# COMPUTE_CLUSTER_ARM_COREPACK_0_COMPUTE_CLUSTER_ARM_COREPACK_0_APBADDR_ETM_CPU0_000730040000h register map
Vendor: Texas Instruments
Registers are 32-bit, read-write, reset 0x0 unless marked. A register's access mark holds for its fields unless they carry their own. Offsets are as the file gives them; [hi:lo] are bit positions; {n}, {i} and the like mark numbered series; <NAME> marks a mode.

## COMPUTE_CLUSTER_ARM_COREPACK_0_APBADDR_ETM_CPU0 (part 2 of 2)
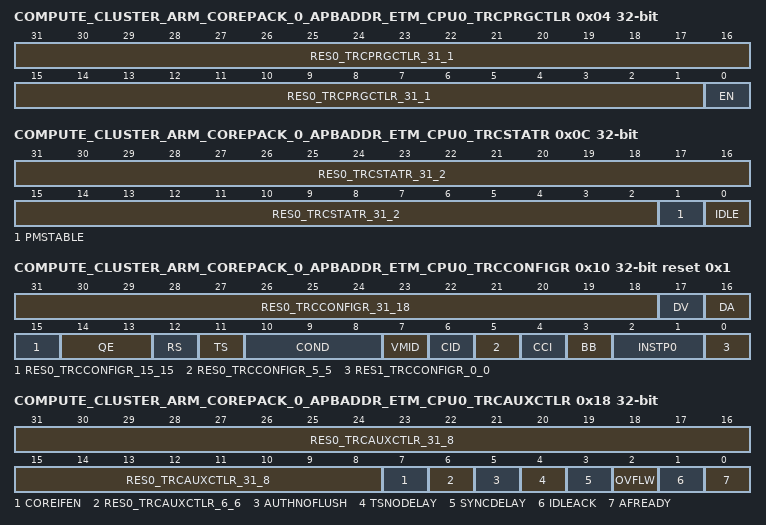
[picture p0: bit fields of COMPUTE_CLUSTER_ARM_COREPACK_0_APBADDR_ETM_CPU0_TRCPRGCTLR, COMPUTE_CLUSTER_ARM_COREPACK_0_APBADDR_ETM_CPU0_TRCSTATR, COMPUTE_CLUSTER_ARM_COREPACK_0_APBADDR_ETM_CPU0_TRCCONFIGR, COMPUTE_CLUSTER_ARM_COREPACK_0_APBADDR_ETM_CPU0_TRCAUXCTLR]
0x04 COMPUTE_CLUSTER_ARM_COREPACK_0_APBADDR_ETM_CPU0_TRCPRGCTLR — Programming Control Register
  [31:1] RES0_TRCPRGCTLR_31_1 — Reserved, RES0.
  [0] EN — Trace unit enable bit. Possible values are: 0 The trace unit is disabled. All trace resources are inactive and no trace is generated. 1 The trace unit is enabled.
0x0C COMPUTE_CLUSTER_ARM_COREPACK_0_APBADDR_ETM_CPU0_TRCSTATR — Status Register
  [31:2] RES0_TRCSTATR_31_2 — Reserved, RES0.
  [1] PMSTABLE — Programmer's model stable bit: 0 The programmer's model is not stable. 1 The programmer's model is stable. When polled, the trace unit trace registers return stable data. The programmer's model is stable when all of the following are true:TRCPRGCTLR.EN==0 or the OS Lock is locked.Reads from trace unit registers return stable data.
  [0] IDLE — Idle status bit: 0 The trace unit is not idle. 1 The trace unit is idle. The trace unit is idle when all of the following are true:TRCPRGCTLR.EN==0 or the OS Lock is locked.The trace unit is drained of any trace.With the exception of the programming interfaces, all external interfaces on the trace unit are quiescent.
0x10 COMPUTE_CLUSTER_ARM_COREPACK_0_APBADDR_ETM_CPU0_TRCCONFIGR reset 0x1 — Trace Configuration Register
  [31:18] RES0_TRCCONFIGR_31_18 — Reserved, RES0.
  [17] DV — Data value tracing bit: 0 Data value tracing is disabled. 1 Data value tracing is enabled when INSTP0 is not 0b00. TRCIDR0.TRCDATA indicates whether this bit is supported. If it is not supported then this bit is RES0.
  [16] DA — Data address tracing bit: 0 Data address tracing is disabled. 1 Data address tracing is enabled when INSTP0 is not 0b00. TRCIDR0.TRCDATA indicates whether this bit is supported. If it is not supported then this bit is RES0.
  [15] RES0_TRCCONFIGR_15_15 — Reserved, RES0.
  [14:13] QE — Q element enable field: 00 Q elements are disabled. 01 Q elements with instruction counts are enabled. Q elements without instruction counts are disabled. 11 Q elements with and without instruction counts are enabled. The value 0b10 is reserved.TRCIDR0.QSUPP indicates which values of this field are implemented.TRCCONFIGR.QE must be set to 0b00 if any of the following are true:TRCCONFIGR.INSTP0 is not 0b00.TRCCONFIGR.COND is not 0b000.TRCCONFIGR.BB is not 0.
  [12] RS — Return stack enable bit. 0 Return stack is disabled. 1 Return stack is enabled. TRCIDR0.RETSTACK indicates whether this bit is supported. If it is not supported then this bit is RES0.
  [11] TS — Global timestamp tracing bit: 0 Global timestamp tracing is disabled. 1 Global timestamp tracing is enabled. TRCTSCTLR controls the insertion of timestamps in the trace. TRCIDR0.TSSIZE indicates whether this bit is supported. If it is not supported then this bit is RES0.
  [10:8] COND — Conditional instruction tracing bit. The permitted values are: 000 Conditional instruction tracing is disabled. 001 Conditional load instructions are traced. 010 Conditional store instructions are traced. 011 Conditional load and store instructions are traced. 111 All conditional instructions are traced. All other values are reserved.TRCIDR0.TRCCOND indicates whether this field is supported. If it is not supported then this field is RES0.
  [7] VMID — VMID tracing bit: 0 VMID tracing is disabled. 1 VMID tracing is enabled. TRCIDR2.VMIDSIZE indicates whether this bit is supported. If it is not supported then this bit is RES0.
  [6] CID — Context ID tracing bit: 0 Context ID tracing is disabled. 1 Context ID tracing is enabled. TRCIDR2.CIDSIZE indicates whether this bit is supported. If it is not supported then this bit is RES0.
  [5] RES0_TRCCONFIGR_5_5 — Reserved, RES0.
  [4] CCI — Cycle counting instruction trace bit: 0 Cycle counting in the instruction trace is disabled. 1 Cycle counting in the instruction trace is enabled. TRCCCCTLR controls the threshold value for cycle counting. TRCIDR0.TRCCCI indicates whether this bit is supported. If it is not supported then this bit is RES0.
  [3] BB — Branch broadcast mode bit: 0 Branch broadcast mode is disabled. 1 Branch broadcast mode is enabled. TRCBBCTLR controls which regions of memory are enabled to use branch broadcasting. TRCIDR0.TRCBB indicates whether this bit is supported. If it is not supported then this bit is RES0.
  [2:1] INSTP0 — Instruction P0 bit. This field controls whether load and store instructions are traced as P0 instructions: 00 Do not trace load and store instructions as P0 instructions. 01 Trace load instructions as P0 instructions. 10 Trace store instructions as P0 instructions. 11 Trace load and store instructions as P0 instructions. TRCIDR0.INSTP0 indicates whether this field is supported. If it is not supported then this field is RES0.
  [0] RES1_TRCCONFIGR_0_0 — Reserved, RES1.
0x18 COMPUTE_CLUSTER_ARM_COREPACK_0_APBADDR_ETM_CPU0_TRCAUXCTLR — Auxiliary Control Register
  [31:8] RES0_TRCAUXCTLR_31_8 — Reserved RES0
  [7] COREIFEN — Keep core interface enabled regardless of trace enable register state
  [6] RES0_TRCAUXCTLR_6_6 — Reserved RES0
  [5] AUTHNOFLUSH — Do not flush trace on de-assertion of authentication inputs. When this bit is set to 1 the trace unit behavior deviates from architecturally-specified behavior.
  [4] TSNODELAY — Do not delay timestamp insertion based on FIFO depth.
  [3] SYNCDELAY — Delay periodic synchronization if FIFO is more than half-full.
  [2] OVFLW — Force an overflow if synchronization is not completed when second synchronization becomes due. When this bit is set to 1 the trace unit behavior deviates from architecturally-specified behavior.
  [1] IDLEACK — Force idle-drain acknowledge high CPU does not wait for trace to drain before entering WFX state. When this bit is set to 1 trace unit behavior deviates from architecturally-specified behavior.
  [0] AFREADY — Always respond to AFREADY immediately. Does not have any interaction with FIFO draining even in WFI state.
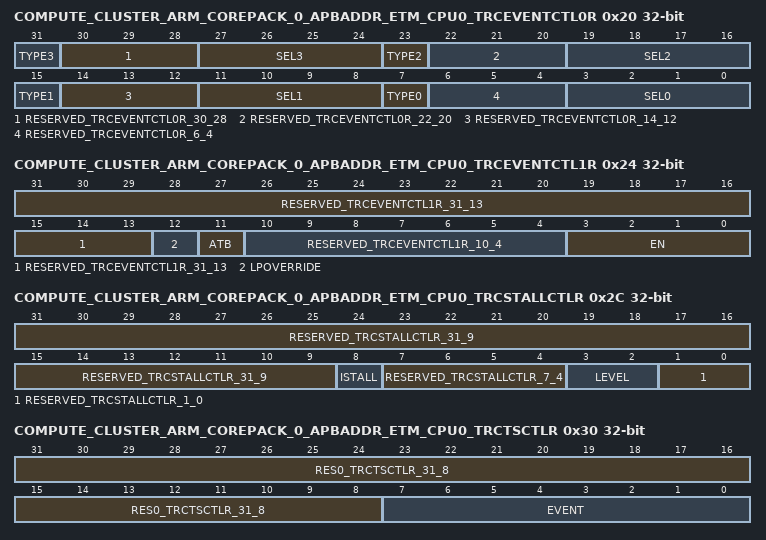
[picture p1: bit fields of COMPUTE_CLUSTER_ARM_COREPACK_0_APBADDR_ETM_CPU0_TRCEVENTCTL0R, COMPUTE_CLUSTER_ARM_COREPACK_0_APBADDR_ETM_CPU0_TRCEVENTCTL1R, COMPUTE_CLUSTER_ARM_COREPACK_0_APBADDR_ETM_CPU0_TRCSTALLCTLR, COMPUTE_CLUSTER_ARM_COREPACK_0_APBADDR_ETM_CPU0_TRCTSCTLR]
0x20 COMPUTE_CLUSTER_ARM_COREPACK_0_APBADDR_ETM_CPU0_TRCEVENTCTL0R — Event Control 0 Register
  [8n+7] TYPE{n} (n=0..3) — Selects the resource type for trace event {n}
  [30:28] RESERVED_TRCEVENTCTL0R_30_28 — Reserved RES0
  [8n+3:8n] SEL{n} (n=0..3) — Selects the resource number based on the value of TYPE{n}
  [22:20] RESERVED_TRCEVENTCTL0R_22_20 — Reserved RES0
  [14:12] RESERVED_TRCEVENTCTL0R_14_12 — Reserved RES0
  [6:4] RESERVED_TRCEVENTCTL0R_6_4 — Reserved RES0
0x24 COMPUTE_CLUSTER_ARM_COREPACK_0_APBADDR_ETM_CPU0_TRCEVENTCTL1R — Event Control 1 Register
  [31:13] RESERVED_TRCEVENTCTL1R_31_13 — Reserved RES0
  [12] LPOVERRIDE — Low power state behavior override
  [11] ATB — ATB trigger enable
  [10:4] RESERVED_TRCEVENTCTL1R_10_4 — Reserved RES0
  [3:0] EN — One bit per event to enable generation of an event element in the instruction trace stream when the selected event occurs
0x2C COMPUTE_CLUSTER_ARM_COREPACK_0_APBADDR_ETM_CPU0_TRCSTALLCTLR — Stall Control Register
  [31:9] RESERVED_TRCSTALLCTLR_31_9 — Reserved RES0
  [8] ISTALL — Controls if the trace unit can stall the processor when the instruction trace buffer space is less than LEVEL
  [7:4] RESERVED_TRCSTALLCTLR_7_4 — Reserved RES0
  [3:2] LEVEL — The field can support 4 monotonic levels from 0b00 to 0b11
  [1:0] RESERVED_TRCSTALLCTLR_1_0 — Reserved RES0
0x30 COMPUTE_CLUSTER_ARM_COREPACK_0_APBADDR_ETM_CPU0_TRCTSCTLR — Global Timestamp Control Register
  [31:8] RES0_TRCTSCTLR_31_8 — Reserved, RES0.
  [7:0] EVENT — An event selector. When the selected event is triggered, the trace unit inserts a global timestamp into the trace streams.
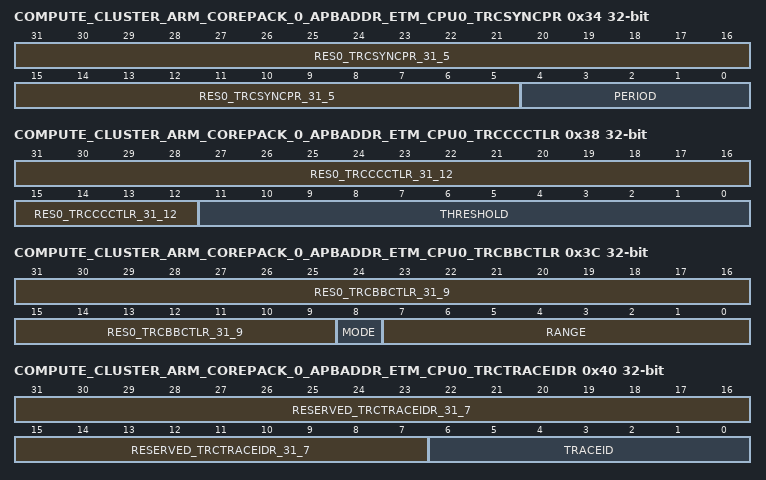
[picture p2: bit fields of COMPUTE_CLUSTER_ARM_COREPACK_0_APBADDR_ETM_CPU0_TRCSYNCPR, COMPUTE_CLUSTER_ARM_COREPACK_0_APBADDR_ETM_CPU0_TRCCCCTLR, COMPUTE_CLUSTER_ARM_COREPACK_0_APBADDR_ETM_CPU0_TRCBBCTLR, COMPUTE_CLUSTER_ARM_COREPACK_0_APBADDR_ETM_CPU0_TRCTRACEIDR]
0x34 COMPUTE_CLUSTER_ARM_COREPACK_0_APBADDR_ETM_CPU0_TRCSYNCPR — Synchronization Period Register
  [31:5] RES0_TRCSYNCPR_31_5 — Reserved, RES0.
  [4:0] PERIOD — Controls how many bytes of trace, the sum of instruction and data, that a trace unit can generate before a periodic trace synchronization request occurs. The number of bytes is always a power of two and the permitted values are: 00000 Periodic trace synchronization requests are disabled. This setting does not disable other types of trace synchronization request. 01000 Periodic trace synchronization request occurs after 2^8, or 256, bytes of trace. 01001 Periodic trace synchronization request occurs after 2^9, or 512, bytes of trace. 01010 Periodic trace synchronization request occurs after 2^10, or 1024, bytes of trace. and so on up to 0b10100, for which the request occurs after 2^20, or 1048576, bytes of trace.Values between 0b00001 and 0b001111 are reserved, as are values from 0b10101 onwards.
0x38 COMPUTE_CLUSTER_ARM_COREPACK_0_APBADDR_ETM_CPU0_TRCCCCTLR — Cycle Count Control Register
  [31:12] RES0_TRCCCCTLR_31_12 — Reserved, RES0.
  [11:0] THRESHOLD — Sets the threshold value for instruction trace cycle counting.The minimum threshold value that can be programmed into THRESHOLD is given in TRCIDR3.CCITMIN.Writing a value of zero might cause UNPREDICTABLE behaviour.
0x3C COMPUTE_CLUSTER_ARM_COREPACK_0_APBADDR_ETM_CPU0_TRCBBCTLR — Branch Broadcast Control Register
  [31:9] RES0_TRCBBCTLR_31_9 — Reserved, RES0.
  [8] MODE — Mode bit: 0 Exclude mode. Branch broadcasting is not enabled in the address range that RANGE defines. If RANGE==0 then branch broadcasting is enabled for the entire memory map. 1 Include mode. Branch broadcasting is enabled in the address range that RANGE defines. If RANGE==0 then the branch broadcasting behavior is UNPREDICTABLE.
  [7:0] RANGE — Address range field. Selects which address range comparator pairs are in use with branch broadcasting. Each bit represents an address range comparator pair, so bit[n] controls the selection of address range comparator pair n. If bit[n] is: 0 The address range that address range comparator pair n defines is not selected. 1 The address range that address range comparator pair n defines is selected.
0x40 COMPUTE_CLUSTER_ARM_COREPACK_0_APBADDR_ETM_CPU0_TRCTRACEIDR — Trace ID Register
  [31:7] RESERVED_TRCTRACEIDR_31_7 — Reserved RES0
  [6:0] TRACEID — Trace ID value. When only instruction tracing is enabled this provides the trace ID.
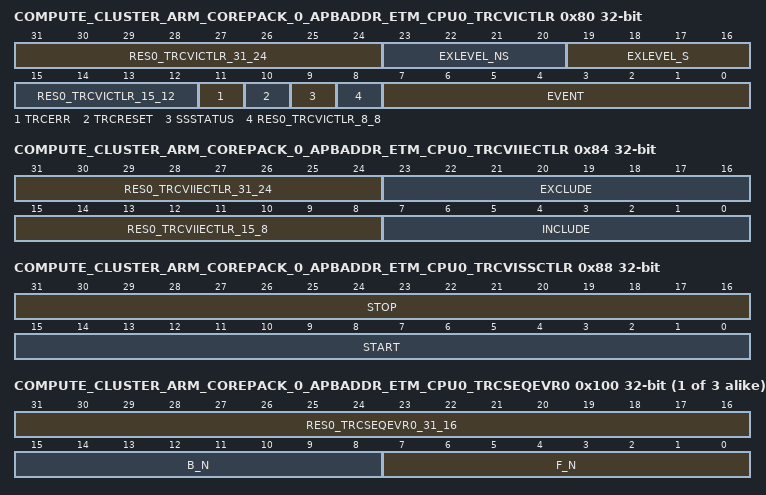
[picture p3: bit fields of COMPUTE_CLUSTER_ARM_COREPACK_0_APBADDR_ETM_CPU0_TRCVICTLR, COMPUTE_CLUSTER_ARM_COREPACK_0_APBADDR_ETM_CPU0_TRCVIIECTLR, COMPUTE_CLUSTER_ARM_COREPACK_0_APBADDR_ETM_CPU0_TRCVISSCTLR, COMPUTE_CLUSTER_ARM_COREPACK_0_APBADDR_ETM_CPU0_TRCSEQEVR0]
0x80 COMPUTE_CLUSTER_ARM_COREPACK_0_APBADDR_ETM_CPU0_TRCVICTLR — ViewInst Main Control Register
  [31:24] RES0_TRCVICTLR_31_24 — Reserved, RES0.
  [23:20] EXLEVEL_NS — In Non-secure state, each bit controls whether instruction tracing is enabled for the corresponding exception level: 0 The trace unit generates instruction trace, in Non-secure state, for exception level n. 1 The trace unit does not generate instruction trace, in Non-secure state, for exception level n. The exception levels are:Bit[20]Exception level 0.Bit[21]Exception level 1.Bit[22]Exception level 2.Bit[23]RAZ/WI. EXLEVEL_NS[3] is never implemented.The content of the field is IMPLEMENTATION DEFINED and is set by the value of TRCIDR3.EXLEVEL_NS. If instruction tracing is not implemented for a given exception level, the corresponding bit in this field is not implemented. Unimplemented bits are RAZ/WI.
  [19:16] EXLEVEL_S — In Secure state, each bit controls whether instruction tracing is enabled for the corresponding exception level: 0 The trace unit generates instruction trace, in Secure state, for exception level n. 1 The trace unit does not generate instruction trace, in Secure state, for exception level n. The exception levels are:Bit[16]Exception level 0.Bit[17]Exception level 1.Bit[18]RAZ/WI. EXLEVEL_S[2] is never implemented.Bit[19]Exception level 3.The content of the field is IMPLEMENTATION DEFINED and is set by the value of TRCIDR3.EXLEVEL_S. If instruction tracing is not implemented for a given exception level, the corresponding bit in this field is not implemented. Unimplemented bits are RAZ/WI.
  [15:12] RES0_TRCVICTLR_15_12 — Reserved, RES0.
  [11] TRCERR — If TRCIDR3.TRCERR==1, this bit controls whether a trace unit must trace a system error exception: 0 The trace unit does not trace a system error exception unless it traces the exception or instruction immediately prior to the system error exception. 1 The trace unit always traces a system error exception. If TRCIDR3.TRCERR==0, this bit is RES0.
  [10] TRCRESET — Controls whether a trace unit must trace a Reset exception: 0 The trace unit does not trace a Reset exception unless it traces the exception or instruction immediately prior to the Reset exception. 1 The trace unit always traces a Reset exception.
  [9] SSSTATUS — IF TRCIDR4.NUMACPAIRS>0 or TRCIDR.NUMPC>0, this bit returns the status of the start-stop logic: 0 The start-stop logic is in the stopped state. 1 The start-stop logic is in the started state. The bit only returns stable data when TRCSTATR.PMSTABLE==1.Before software enables the trace unit, TRCPRGCTLR.EN==1, it must write to this bit to set the initial state of the start-stop logic. If the start-stop logic is not used then set this bit to 1. ARM recommends that the value of this bit is set before each trace run begins.If TRCIDR4.NUMACPAIRS==0 and TRCIDR4.NUMPC==0, this bit is RES0, indicating that the start-stop logic is not implemented.
  [8] RES0_TRCVICTLR_8_8 — Reserved, RES0.
  [7:0] EVENT — An event selector. [TODO: Add the bit assignments for EVENT fields into the descriptions directly?]
0x84 COMPUTE_CLUSTER_ARM_COREPACK_0_APBADDR_ETM_CPU0_TRCVIIECTLR — ViewInst Include-Exclude Control Register
  [31:24] RES0_TRCVIIECTLR_31_24 — Reserved, RES0.
  [23:16] EXCLUDE — 0 1 The implemented width of the field, n, is IMPLEMENTATION DEFINED and is set by the value of TRCIDR4.NUMACPAIRS. Unimplemented bits are RAZ/WI.
  [15:8] RES0_TRCVIIECTLR_15_8 — Reserved, RES0.
  [7:0] INCLUDE — Include range field. Selects which address range comparator pairs are in use with ViewInst include control. Each bit represents an address range comparator pair, so bit[m] controls the selection of address range comparator pair m. If bit[m] is: 0 The address range that address range comparator pair m defines is not selected for ViewInst include control. 1 The address range that address range comparator pair m defines is selected for ViewInst include control. The implemented width of the field, n, is IMPLEMENTATION DEFINED and is set by the value of TRCIDR4.NUMACPAIRS. Unimplemented bits are RAZ/WI.Selecting no include comparators indicates that all instructions are included by default. The exclude control then indicates which ranges are excluded.
0x88 COMPUTE_CLUSTER_ARM_COREPACK_0_APBADDR_ETM_CPU0_TRCVISSCTLR — ViewInst Start-Stop Control Register
  [31:16] STOP — Selects which single address comparators are in use with ViewInst start-stop control, for the purpose of stopping trace. Each bit represents a single address comparator, so bit[m] controls the selection of single address comparator m-16. If bit[m] is: 0 The single address comparator m-16 is not selected as a stop resource. 1 The single address comparator m-16 is selected as a stop resource. The implemented width of the field, n, is IMPLEMENTATION DEFINED and is set by the value of 2 x TRCIDR4.NUMACPAIRS. Unimplemented bits are RAZ/WI.
  [15:0] START — Selects which single address comparators are in use with ViewInst start-stop control, for the purpose of starting trace. Each bit represents a single address comparator, so bit[n] controls the selection of single address comparator n. If bit[n] is: 0 The single address comparator n is not selected as a start resource. 1 The single address comparator n is selected as a start resource. The implemented width of the field, n, is IMPLEMENTATION DEFINED and is set by the value of 2 x TRCIDR4.NUMACPAIRS. Unimplemented bits are RAZ/WI.
{0x100+4i} COMPUTE_CLUSTER_ARM_COREPACK_0_APBADDR_ETM_CPU0_TRCSEQEVR{i} (i=0..2) — Sequencer State Transition Control Registers {i}
  [31:16] RES0_TRCSEQEVR{i}_31_16 — Reserved, RES0.
  [15:8] B_N — Backward field. Contains an event number. When the event occurs then the sequencer state moves from state n+1 to state n.For example, for TRCSEQEVR2, if B2==0x14 then when event 0x14 occurs, the sequencer moves from state 3 to state 2.
  [7:0] F_N — Forward field. Contains an event number. When the event occurs then the sequencer state moves from state n to state n+1.For example, for TRCSEQEVR1, if F1==0x12 then when event 0x12 occurs, the sequencer moves from state 1 to state 2.
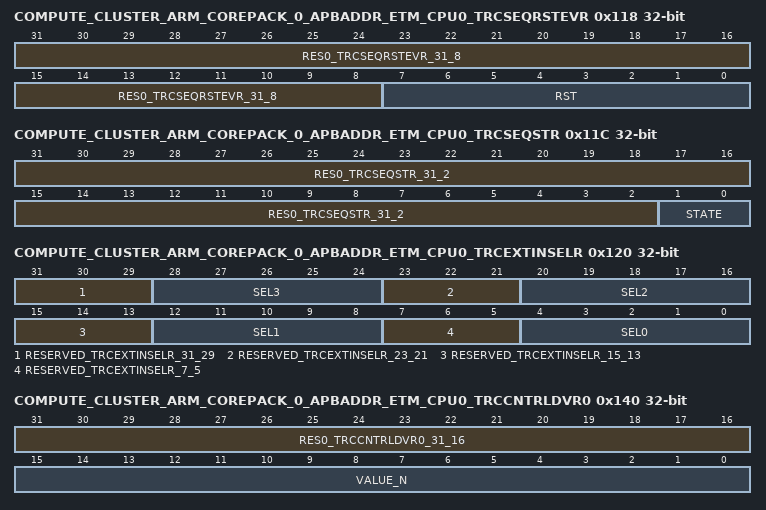
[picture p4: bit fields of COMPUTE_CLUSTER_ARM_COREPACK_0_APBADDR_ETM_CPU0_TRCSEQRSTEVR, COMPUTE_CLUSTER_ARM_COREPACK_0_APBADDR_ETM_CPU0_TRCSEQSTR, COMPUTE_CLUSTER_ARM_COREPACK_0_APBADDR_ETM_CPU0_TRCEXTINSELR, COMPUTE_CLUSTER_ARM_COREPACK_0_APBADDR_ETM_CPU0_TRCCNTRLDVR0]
0x118 COMPUTE_CLUSTER_ARM_COREPACK_0_APBADDR_ETM_CPU0_TRCSEQRSTEVR — Sequencer Reset Control Register
  [31:8] RES0_TRCSEQRSTEVR_31_8 — Reserved, RES0.
  [7:0] RST — Contains an event number. When the event occurs then the sequencer state moves to state 0.
0x11C COMPUTE_CLUSTER_ARM_COREPACK_0_APBADDR_ETM_CPU0_TRCSEQSTR — Sequencer State Register
  [31:2] RES0_TRCSEQSTR_31_2 — Reserved, RES0.
  [1:0] STATE — Sets or returns the state of the sequencer: 00 State 0. 01 State 1. 10 State 2. 11 State 3.
0x120 COMPUTE_CLUSTER_ARM_COREPACK_0_APBADDR_ETM_CPU0_TRCEXTINSELR — External Input Select Register
  [31:29] RESERVED_TRCEXTINSELR_31_29 — Reserved RES0
  [28:24] SEL3 — Selects an event from the external input bus for External Input Resource 3.
  [23:21] RESERVED_TRCEXTINSELR_23_21 — Reserved RES0
  [20:16] SEL2 — Selects an event from the external input bus for External Input Resource 2
  [15:13] RESERVED_TRCEXTINSELR_15_13 — Reserved RES0
  [12:8] SEL1 — Selects an event from the external input bus for External Input Resource 1
  [7:5] RESERVED_TRCEXTINSELR_7_5 — Reserved RES0
  [4:0] SEL0 — Selects an event from the external input bus for External Input Resource 0
0x140 COMPUTE_CLUSTER_ARM_COREPACK_0_APBADDR_ETM_CPU0_TRCCNTRLDVR0 — Counter Reload Value Registers 0
  [31:16] RES0_TRCCNTRLDVR0_31_16 — Reserved, RES0.
  [15:0] VALUE_N — Contains the reload value for counter <n>. When a reload event occurs for counter <n> then the trace unit copies the VALUE<n> field into counter <n>.
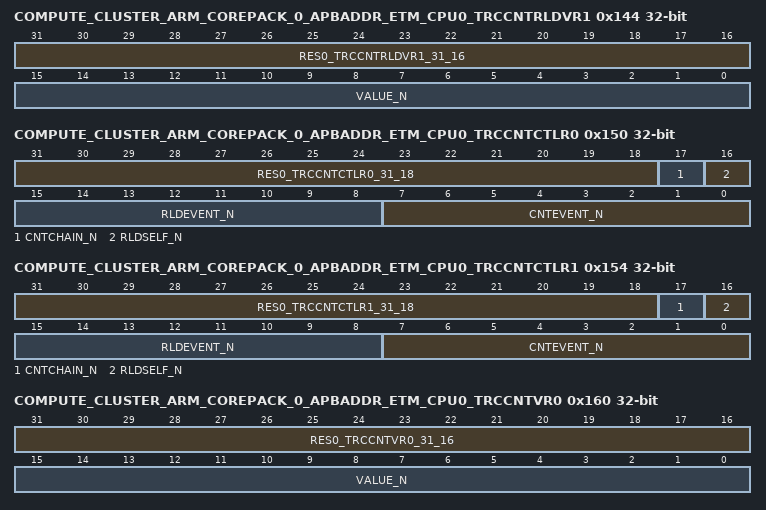
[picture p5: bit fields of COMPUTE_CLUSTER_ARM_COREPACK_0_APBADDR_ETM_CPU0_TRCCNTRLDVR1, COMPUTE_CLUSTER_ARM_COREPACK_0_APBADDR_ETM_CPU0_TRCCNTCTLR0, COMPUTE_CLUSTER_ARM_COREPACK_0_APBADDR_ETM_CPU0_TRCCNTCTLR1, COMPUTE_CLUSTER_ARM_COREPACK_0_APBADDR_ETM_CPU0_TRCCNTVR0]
0x144 COMPUTE_CLUSTER_ARM_COREPACK_0_APBADDR_ETM_CPU0_TRCCNTRLDVR1 — Counter Reload Value Registers 1
  [31:16] RES0_TRCCNTRLDVR1_31_16 — Reserved, RES0.
  [15:0] VALUE_N — Contains the reload value for counter <n>. When a reload event occurs for counter <n> then the trace unit copies the VALUE<n> field into counter <n>.
0x150 COMPUTE_CLUSTER_ARM_COREPACK_0_APBADDR_ETM_CPU0_TRCCNTCTLR0 — Counter Control Register 0
  [31:18] RES0_TRCCNTCTLR0_31_18 — Reserved, RES0.
  [17] CNTCHAIN_N — For TRCCNTCTLR3 and TRCCNTCTLR1, controls whether counter <n> decrements when a reload event occurs for counter <n-1>: 0 1 For TRCCNTCTLR2 and TRCCNTCTLR0, this bit is RES0.
  [16] RLDSELF_N — Controls whether a reload event occurs for counter <n>, when counter <n> reaches zero: 0 The trace unit does not generate a reload event. 1 The trace unit generates a reload event for counter <n>, provided that the event resource that CNTEVENT<n> specifies is active.
  [15:8] RLDEVENT_N — Selects an event, that when it occurs causes a reload event for counter <n>.
  [7:0] CNTEVENT_N — Selects an event, that when it occurs causes counter <n> to decrement.
0x154 COMPUTE_CLUSTER_ARM_COREPACK_0_APBADDR_ETM_CPU0_TRCCNTCTLR1 — Counter Control Register 1
  [31:18] RES0_TRCCNTCTLR1_31_18 — Reserved, RES0.
  [17] CNTCHAIN_N — For TRCCNTCTLR3 and TRCCNTCTLR1, controls whether counter <n> decrements when a reload event occurs for counter <n-1>: 0 1 For TRCCNTCTLR2 and TRCCNTCTLR0, this bit is RES0.
  [16] RLDSELF_N — Controls whether a reload event occurs for counter <n>, when counter <n> reaches zero: 0 The trace unit does not generate a reload event. 1 The trace unit generates a reload event for counter <n>, provided that the event resource that CNTEVENT<n> specifies is active.
  [15:8] RLDEVENT_N — Selects an event, that when it occurs causes a reload event for counter <n>.
  [7:0] CNTEVENT_N — Selects an event, that when it occurs causes counter <n> to decrement.
0x160 COMPUTE_CLUSTER_ARM_COREPACK_0_APBADDR_ETM_CPU0_TRCCNTVR0 — Counter Value Registers 0
  [31:16] RES0_TRCCNTVR0_31_16 — Reserved, RES0.
  [15:0] VALUE_N — Contains the count value of counter <n>.
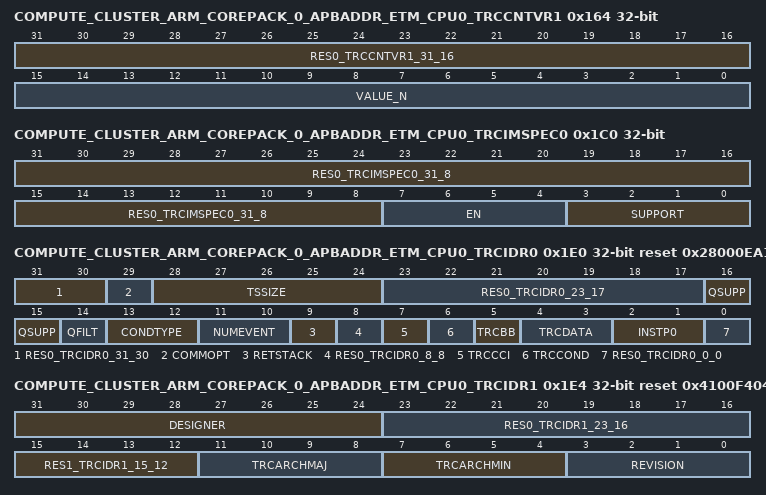
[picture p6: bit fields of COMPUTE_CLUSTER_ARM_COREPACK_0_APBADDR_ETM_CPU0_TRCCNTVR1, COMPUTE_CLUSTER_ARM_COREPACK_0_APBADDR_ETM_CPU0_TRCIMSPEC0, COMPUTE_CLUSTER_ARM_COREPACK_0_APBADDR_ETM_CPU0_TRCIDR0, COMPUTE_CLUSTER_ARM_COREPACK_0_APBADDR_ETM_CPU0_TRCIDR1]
0x164 COMPUTE_CLUSTER_ARM_COREPACK_0_APBADDR_ETM_CPU0_TRCCNTVR1 — Counter Value Registers 1
  [31:16] RES0_TRCCNTVR1_31_16 — Reserved, RES0.
  [15:0] VALUE_N — Contains the count value of counter <n>.
0x180 COMPUTE_CLUSTER_ARM_COREPACK_0_APBADDR_ETM_CPU0_TRCIDR8 — ID Register 8
  [31:0] MAXSPEC — Indicates the maximum speculation depth of the instruction trace stream. This is the maximum number of P0 elements in the trace stream that can be speculative at any time.
0x184 COMPUTE_CLUSTER_ARM_COREPACK_0_APBADDR_ETM_CPU0_TRCIDR9 — ID Register 9
  [31:0] NUMP0KEY — Indicates the number of P0 right-hand keys that the trace unit can use. A value of 0 or 1 indicates one P0 key.
0x188 COMPUTE_CLUSTER_ARM_COREPACK_0_APBADDR_ETM_CPU0_TRCIDR10 — ID Register 10
  [31:0] NUMP1KEY — Indicates the number of P1 right-hand keys that the trace unit can use. The number includes normal and special keys.
0x18C COMPUTE_CLUSTER_ARM_COREPACK_0_APBADDR_ETM_CPU0_TRCIDR11 — ID Register 11
  [31:0] NUMP1SPC — Indicates the number of special P1 right-hand keys that the trace unit can use.
0x190 COMPUTE_CLUSTER_ARM_COREPACK_0_APBADDR_ETM_CPU0_TRCIDR12 — ID Register 12
  [31:0] NUMCONDKEY — Indicates the number of conditional instruction right-hand keys that the trace unit can use. The number includes normal and special keys.
0x194 COMPUTE_CLUSTER_ARM_COREPACK_0_APBADDR_ETM_CPU0_TRCIDR13 — ID Register 13
  [31:0] NUMCONDSPC — Indicates the number of special conditional instruction right-hand keys that the trace unit can use.
0x1C0 COMPUTE_CLUSTER_ARM_COREPACK_0_APBADDR_ETM_CPU0_TRCIMSPEC0 — Implementation Specific Register 0
  [31:8] RES0_TRCIMSPEC0_31_8 — Reserved, RES0.
  [7:4] EN — If SUPPORT is not 0b0000, controls whether the IMPLEMENTATION DEFINED features are enabled. The permitted values are: 0000 The IMPLEMENTATION DEFINED features are not enabled. The trace unit must behave as if the IMPLEMENTATION DEFINED features are not supported. and any other value, which indicates that the trace unit behavior is IMPLEMENTATION DEFINED.If SUPPORT is 0b0000, this field is RES0.
  [3:0] SUPPORT — Indicates whether the implementation supports IMPLEMENTATION DEFINED features. The permitted values are: 0000 No IMPLEMENTATION DEFINED features are supported. The EN field is RES0. and any other value, which indicates that IMPLEMENTATION DEFINED features are supported. Use of these values requires written permission from ARM.
0x1E0 COMPUTE_CLUSTER_ARM_COREPACK_0_APBADDR_ETM_CPU0_TRCIDR0 reset 0x28000EA1 — ID Register 0
  [31:30] RES0_TRCIDR0_31_30 — Reserved, RES0.
  [29] COMMOPT — Conditional instruction tracing support bit. Indicates if the trace unit supports conditional instruction tracing: 0 Conditional instruction tracing is not supported. 1 Conditional instruction tracing is supported, so TRCCONFIGR.COND is supported.
  [28:24] TSSIZE — Global timestamp size field. The permitted values are: 00000 Global timestamping is not implemented. 00110 Implementation supports a maximum global timestamp of 48bits. 01000 Implementation supports a maximum global timestamp of 64bits. All other values are reserved.When global timestamping is implemented then TRCCONFIGR.TS and TRCTSCTLR are supported.
  [23:17] RES0_TRCIDR0_23_17 — Reserved, RES0.
  [16:15] QSUPP — Q element support field. The permitted values are: 00 Q element support is not implemented. TRCCONFIGR.QE is RES0. 01 Q element support is implemented, and only supports Q elements with instruction counts. TRCCONFIGR.QE can only take the values 0b00 or 0b01. 10 Q element support is implemented, and only supports Q elements without instruction counts. TRCCONFIGR.QE can only take the values 0b00 or 0b11. 11 Q element support is implemented, and supports both Q elements with instruction counts and Q elements without instruction counts. TRCCONFIGR.QE is fully implemented.
  [14] QFILT — Q element filtering support field. The permitted values are: 0 Q element filtering is not implemented. 1 Q element filtering is implemented. TRCQCTLR is implemented. When QSUPP==0b00, this field is RES0.
  [13:12] CONDTYPE — Conditional tracing field. The permitted values are: 00 The trace unit indicates only if a conditional instruction is a pass or fail. 01 The trace unit provides the Current Program Status Register [CPSR] status, for a conditional instruction. All other values are reserved.
  [11:10] NUMEVENT — Number of events field. Indicates how many events the trace unit supports: 00 The trace unit supports 1 event. 01 The trace unit supports 2 events. 10 The trace unit supports 3 events. 11 The trace unit supports 4 events. This field controls how many fields are supported in TRCEVENTCTL0R, and indicates the size of TRCEVENTCTL1R.INSTEN.
  [9] RETSTACK — Return stack bit. Indicates if the implementation supports a return stack: 0 Return stack is not implemented. 1 Return stack is implemented, so TRCCONFIGR.RS is supported.
  [8] RES0_TRCIDR0_8_8 — Reserved, RES0.
  [7] TRCCCI — Cycle counting instruction bit. Indicates if the trace unit supports cycle counting for instructions: 0 Cycle counting in the instruction trace is not implemented. 1 Cycle counting in the instruction trace is implemented, so TRCCONFIGR.CCI and TRCCCCTLR are supported.
  [6] TRCCOND — Conditional instruction tracing support bit. Indicates if the trace unit supports conditional instruction tracing: 0 Conditional instruction tracing is not supported. 1 Conditional instruction tracing is supported, so TRCCONFIGR.COND is supported.
  [5] TRCBB — Branch broadcast tracing support bit. Indicates if the trace unit supports branch broadcast tracing: 0 Branch broadcast tracing is not supported. 1 Branch broadcast tracing is supported, so TRCCONFIGR.BB and TRCBBCTLR are supported.
  [4:3] TRCDATA — Conditional tracing field. The permitted values are: 00 Data tracing is not supported. 11 Tracing of data addresses and data values is supported, so TRCCONFIGR.DA, TRCCONFIGR.DV, TRCSTALLCTLR.DATADISCARD, TRCSTALLCTLR.INSTPRIORITY, TRCSTALLCTLR.DSTALL, and TRCEVENTCTL1R.DATAEN are supported. All other values are reserved.
  [2:1] INSTP0 — P0 tracing support field. The permitted values are: 00 Tracing of load and store instructions as P0 elements is not supported. 11 Tracing of load and store instructions as P0 elements is supported, so TRCCONFIGR.INSTP0 is supported. All other values are reserved.
  [0] RES0_TRCIDR0_0_0 — Reserved, RES0.
0x1E4 COMPUTE_CLUSTER_ARM_COREPACK_0_APBADDR_ETM_CPU0_TRCIDR1 reset 0x4100F404 — ID Register 1
  [31:24] DESIGNER — Indicates which company designed the trace unit. The permitted values are: 01000001 ARM Limited. 01000100 Digital Equipment Corporation. 01001101 Motorola, Freescale Semiconductor Inc. 01010001 QUALCOMM Inc. 01010110 Marvell Semiconductor Inc. 01101001 Intel Corporation. All other values are reserved.
  [23:16] RES0_TRCIDR1_23_16 — Reserved, RES0.
  [15:12] RES1_TRCIDR1_15_12 — Reserved, RES1.
  [11:8] TRCARCHMAJ — Indicates the major version of the ETM architecture. The permitted value is: 100 ETMv4. All other values are reserved.
  [7:4] TRCARCHMIN — Indicates the minor version of the ETM architecture. The permitted value is: 0 ETMv4 minor version 0. All other values are reserved.
  [3:0] REVISION — Returns an IMPLEMENTATION DEFINED value that identifies the revision of the trace registers and the OS Save and Restore registers.ARM recommends:That the initial implementation sets REVISION==0x0 and the field then increments for any subsequent implementations. However, it is acceptable to omit some values or use another scheme to identify the revision number.That TRCPIDR2.REVISION==TRCIDR1.REVISION. However, in situations where it is difficult to align these fields, such as with a metal layer fix, then it is acceptable to change the REVISION fields independently.
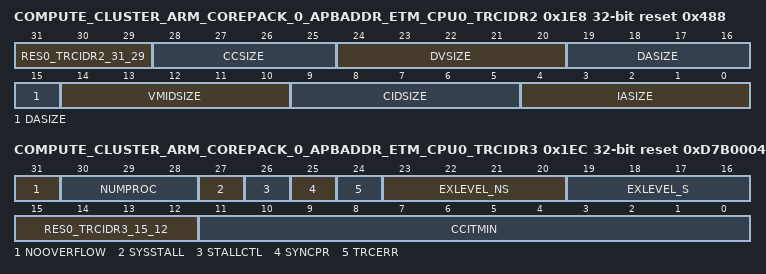
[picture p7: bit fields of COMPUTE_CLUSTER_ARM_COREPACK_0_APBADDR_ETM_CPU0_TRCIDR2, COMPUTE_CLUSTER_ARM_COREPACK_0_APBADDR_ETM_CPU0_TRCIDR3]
0x1E8 COMPUTE_CLUSTER_ARM_COREPACK_0_APBADDR_ETM_CPU0_TRCIDR2 reset 0x488 — ID Register 2
  [31:29] RES0_TRCIDR2_31_29 — Reserved, RES0.
  [28:25] CCSIZE — Indicates the size of the cycle counter in bits minus 12. 0000 The cycle counter is 12 bits in length. 0001 The cycle counter is 13 bits in length. and so on up to 0b1000, indicating the cycle counter is 20 bits in length.All other values are reserved.If cycle counting is not implemented, as indicated by TRCIDR0.TRCCCI, this field is 0b0000.
  [24:20] DVSIZE — Indicates the data value size in bytes. The permitted values are: 00000 Data value tracing is not supported. Therefore, an implementation must also set TRCIDR0.TRCDATA==0b00. 00100 Maximum of 32-bit data value size. 01000 Maximum of 64-bit data value size. All other values are reserved.
  [19:15] DASIZE — Indicates the data address size in bytes. The permitted values are: 00000 Data address tracing is not supported. Therefore, an implementation must also set TRCIDR0.TRCDATA==0b00. 00100 Maximum of 32-bit data address size. 01000 Maximum of 64-bit data address size. All other values are reserved.
  [14:10] VMIDSIZE — Indicates the VMID size. The permitted values are: 00000 VMID tracing is not supported. 00001 Maximum of 8-bit VMID size, so TRCCONFIGR.VMID is supported. All other values are reserved.
  [9:5] CIDSIZE — Indicates the Context ID size. The permitted values are: 00000 Context ID tracing is not supported. 00100 Maximum of 32-bit Context ID size, so TRCCONFIGR.CID is supported. All other values are reserved.
  [4:0] IASIZE — Indicates the instruction address size. The permitted values are: 00100 Maximum of 32-bit address size. 01000 Maximum of 64-bit address size. All other values are reserved.
0x1EC COMPUTE_CLUSTER_ARM_COREPACK_0_APBADDR_ETM_CPU0_TRCIDR3 reset 0xD7B0004 — ID Register 3
  [31] NOOVERFLOW — Indicates if TRCSTALLCTLR.NOOVERFLOW is supported: 0 TRCSTALLCTLR.NOOVERFLOW is not supported, or STALLCTL==0. 1 TRCSTALLCTLR.NOOVERFLOW is supported.
  [30:28] NUMPROC — Indicates the number of processors available for tracing. The possible values are: 000 The trace unit can trace one processor. 001 The trace unit can trace two processors. 010 The trace unit can trace three processors. and so on up to 0b111, which indicates the trace unit can trace eight processors.This field sets the maximum value of TRCPROCSELR.PROCSEL.
  [27] SYSSTALL — Indicates if the implementation can support stall control: 0 The system does not support stall control of the processor. 1 The system can support stall control of the processor. The system supports stalling of the processor only when SYSSTALL==1 and STALLCTL==1.
  [26] STALLCTL — Indicates if TRCSTALLCTLR is supported: 0 TRCSTALLCTLR is not supported. 1 TRCSTALLCTLR is supported.
  [25] SYNCPR — Indicates if an implementation has a fixed synchronization period: 0 TRCSYNCPR is read-write so software can change the synchronization period. 1 TRCSYNCPR is read-only so the synchronization period is fixed.
  [24] TRCERR — Indicates if TRCVICTLR.TRCERR is supported: 0 TRCVICTLR.TRCERR is not supported 1 TRCVICTLR.TRCERR is supported.
  [23:20] EXLEVEL_NS — In Non-secure state, each bit indicates whether instruction tracing is supported for the corresponding exception level: 0 In Non-secure state, exception level n is not supported so the corresponding bits in TRCACATRn.EXLEVEL_NS and TRCVICTLR.EXLEVEL_NS are not supported. 1 In Non-secure state, exception level n is supported so the corresponding bits in TRCACATRn.EXLEVEL_NS and TRCVICTLR.EXLEVEL_NS are supported. The exception levels are:Bit[20]Exception level 0.Bit[21]Exception level 1.Bit[22]Exception level 2.Bit[23]SBZ. EXLEVEL_NS[3] is never implemented.
  [19:16] EXLEVEL_S — In Secure state, each bit indicates whether instruction tracing is supported for the corresponding exception level: 0 In Secure state, exception level n is not supported so the corresponding bits in TRCACATRn.EXLEVEL_S and TRCVICTLR.EXLEVEL_S are not supported. 1 In Secure state, exception level n is supported so the corresponding bits in TRCACATRn.EXLEVEL_S and TRCVICTLR.EXLEVEL_S are supported. The exception levels are:Bit[16]Exception level 0.Bit[17]Exception level 1.Bit[18]SBZ. EXLEVEL_S[2] is never implemented.Bit[19]Exception level 3.
  [15:12] RES0_TRCIDR3_15_12 — Reserved, RES0.
  [11:0] CCITMIN — Indicates the minimum value that can be programmed in TRCCCCTLR.THRESHOLD.When cycle counting in the instruction trace is supported, that is TRCIDR0.TRCCCI==1, then the minimum value of this field is 0x001, otherwise it is 0x000.
